VERSION ""

NS_ :

BS_:

BU_: GMLAN NEO
VAL_TABLE_ GearShifter 3 "Park" 0 "Drive/Low" ;
VAL_TABLE_ DriverDoorStatus 1 "Opened" 0 "Closed" ;
VAL_TABLE_ LKAGapButton 2 "???" 1 "??" 0 "None" ;
VAL_TABLE_ CruiseButtons 6 "Cancel" 5 "Main" 3 "Set" 2 "Resume" 1 "None" ;
VAL_TABLE_ CruiseControlActive 1 "Active" 0 "Inactive" ;
VAL_TABLE_ BlinkerStatus 1 "Active" 0 "Inactive" ;

BO_ 2422407168 DriverDoorStatus: 1 GMLAN
 SG_ DriverDoorOpened : 0|1@0+ (1,0) [0|0] ""  NEO

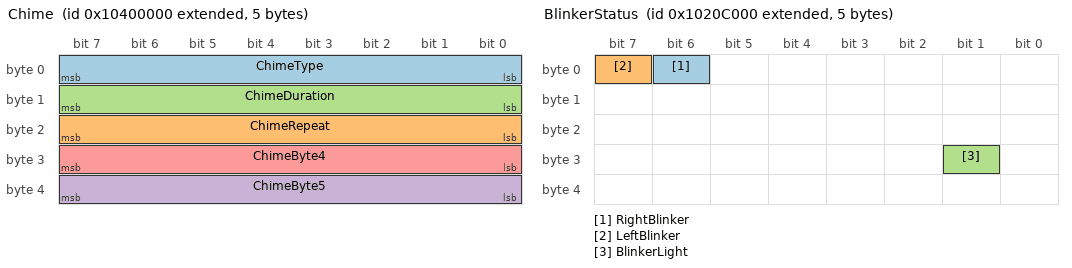
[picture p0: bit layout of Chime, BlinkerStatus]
BO_ 2420113408 Chime: 5 NEO
 SG_ ChimeType : 7|8@0+ (1,0) [0|0] ""  GMLAN
 SG_ ChimeRepeat : 23|8@0+ (1,0) [0|0] ""  GMLAN
 SG_ ChimeDuration : 15|8@0+ (1,0) [0|0] ""  GMLAN
 SG_ ChimeByte5 : 39|8@0+ (1,0) [0|0] ""  GMLAN
 SG_ ChimeByte4 : 31|8@0+ (1,0) [0|0] ""  GMLAN

BO_ 2418065408 BlinkerStatus: 5 GMLAN
 SG_ RightBlinker : 6|1@0+ (1,0) [0|0] ""  NEO
 SG_ LeftBlinker : 7|1@0+ (1,0) [0|0] ""  NEO
 SG_ BlinkerLight : 25|1@0+ (1,0) [0|0] ""  NEO

BO_ 2418278400 SteeringWheelAngle: 8 GMLAN
 SG_ SteeringWheelAngle : 39|16@0- (0.0625,0) [-540|540] "deg"  NEO

BO_ 2418851840 GearShifter: 8 GMLAN
 SG_ GearShifter : 17|2@0+ (1,0) [0|3] ""  NEO

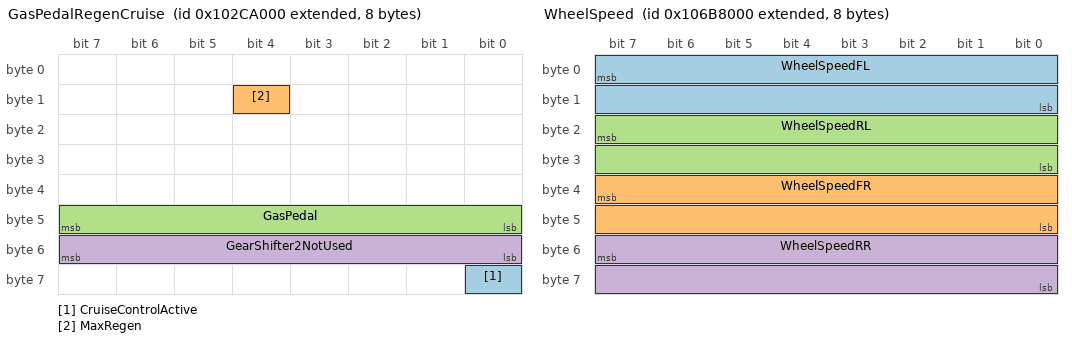
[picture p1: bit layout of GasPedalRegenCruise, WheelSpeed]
BO_ 2418843648 GasPedalRegenCruise: 8 GMLAN
 SG_ CruiseControlActive : 56|1@0+ (1,0) [0|0] ""  GMLAN
 SG_ MaxRegen : 12|1@0+ (1,0) [0|1] ""  GMLAN,NEO
 SG_ GasPedal : 47|8@0+ (1,0) [0|254] ""  GMLAN,NEO
 SG_ GearShifter2NotUsed : 55|8@0+ (1,0) [0|255] ""  GMLAN,NEO

BO_ 2418343936 BrakePedal: 2 GMLAN
 SG_ BrakeLevel : 2|2@0+ (1,0) [0|3] ""  NEO
 SG_ BrakeSensor : 15|8@0+ (1,0) [0|255] ""  NEO

BO_ 2422964224 WheelSpeed: 8 GMLAN
 SG_ WheelSpeedFL : 7|16@0+ (0.01,0) [0|70] "yd/s"  NEO
 SG_ WheelSpeedFR : 39|16@0+ (0.01,0) [0|70] "yd/s"  NEO
 SG_ WheelSpeedRL : 23|16@0+ (0.01,0) [0|70] "yd/s"  NEO
 SG_ WheelSpeedRR : 55|16@0+ (0.01,0) [0|70] "yd/s"  NEO

BO_ 2418081792 VehicleSpeed: 8 GMLAN
 SG_ VehicleSpeed1 : 7|16@0+ (0.01,0) [0|100] "mph"  NEO
 SG_ VehicleSpeed2 : 39|16@0+ (0.01,0) [0|100] "mph"  NEO

BO_ 2423619584 CruiseButtons: 3 GMLAN
 SG_ CruiseButtons : 3|3@0+ (1,0) [0|12] ""  NEO

BO_ 2423611392 CruiseButtons2: 1 GMLAN
 SG_ LKAGapButton : 1|2@0+ (1,0) [0|2] ""  NEO

BO_ 2423439545 LeftRadar: 2 GMLAN
 SG_ BSM_Indicator_Light : 4|1@0+ (1,0) [0|1] "" XXX

BO_ 2423464027 RightRadar: 2 GMLAN
 SG_ BSM_Indicator_Light : 0|1@0+ (1,0) [0|1] "" XXX

BA_DEF_  "UseGMParameterIDs" INT 0 0;
BA_DEF_  "ProtocolType" STRING ;
BA_DEF_  "BusType" STRING ;
BA_DEF_DEF_  "UseGMParameterIDs" 1;
BA_DEF_DEF_  "ProtocolType" "GMLAN";
BA_DEF_DEF_  "BusType" "";
BA_ "BusType" "CAN";
VAL_ 2422407168 DriverDoorOpened 1 "Opened" 0 "Closed" ;
VAL_ 2418065408 RightBlinker 1 "Active" 0 "Inactive" ;
VAL_ 2418065408 LeftBlinker 1 "Active" 0 "Inactive" ;
VAL_ 2418065408 BlinkerLight 1 "Active" 0 "Inactive" ;
VAL_ 2418851840 GearShifter 3 "Park" 0 "Drive/Low" ;
VAL_ 2418843648 CruiseControlActive 1 "Active" 0 "Inactive" ;
VAL_ 2423619584 CruiseButtons 6 "Cancel" 5 "Main" 3 "Set" 2 "Resume" 1 "None" ;
VAL_ 2423611392 LKAGapButton 2 "???" 1 "??" 0 "None" ;
VAL_ 2423439545 BSM_Indicator_Light 0 "Disabled" 1 "Enabled";
VAL_ 2423464027 BSM_Indicator_Right 0 "Disabled" 1 "Enabled";
